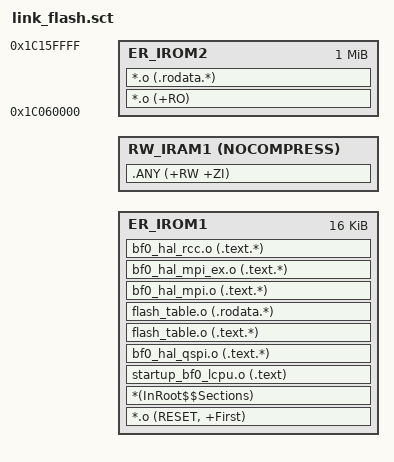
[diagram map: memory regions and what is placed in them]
#! armclang -E --target=arm-arm-none-eabi -mcpu=cortex-m33 -xc
#include "../rtconfig.h"
#include "../../../../../../drivers/cmsis/sf32lb58x/mem_map.h"


; *************************************************************
; *** Scatter-Loading Description File generated by uVision ***
; *************************************************************

LR_IROM1 LCPU_RAM_CODE_START_ADDR LCPU_RAM_CODE_SIZE {    ; load region size_region
  ER_IROM1 LCPU_RAM_CODE_START_ADDR 0x4000  {  ; load address = execution address
   *.o (RESET, +First)
   *(InRoot$$Sections)
   startup_bf0_lcpu.o (.text)
   bf0_hal_qspi.o (.text.*)
   flash_table.o (.text.*)
   flash_table.o (.rodata.*)
   bf0_hal_mpi.o (.text.*)
   bf0_hal_mpi_ex.o (.text.*)
   bf0_hal_rcc.o   (.text.*)
  }
  
  
  RW_IRAM1 AlignExpr(LPSYS_RAM_BASE+ImageLength(ER_IROM1), 16) ALIGN 16 NOCOMPRESS  {  ; RW data
   .ANY (+RW +ZI)
  }
  ; Load Address must be equal to Exec Address
  ScatterAssert((LoadBase(RW_IRAM1) OR 0x20000000) == ImageBase(RW_IRAM1))
  ScatterAssert((ImageLength(ER_IROM1)+ImageLength(RW_IRAM1)+LCPU_MBOX_SIZE)<LPSYS_RAM_SIZE)
}


LR_IROM2 0x1c060000 0x100000 {
	ER_IROM2 0x1c060000 0x100000 {
	*.o (+RO)
    *.o (.rodata.*)
	}

}


